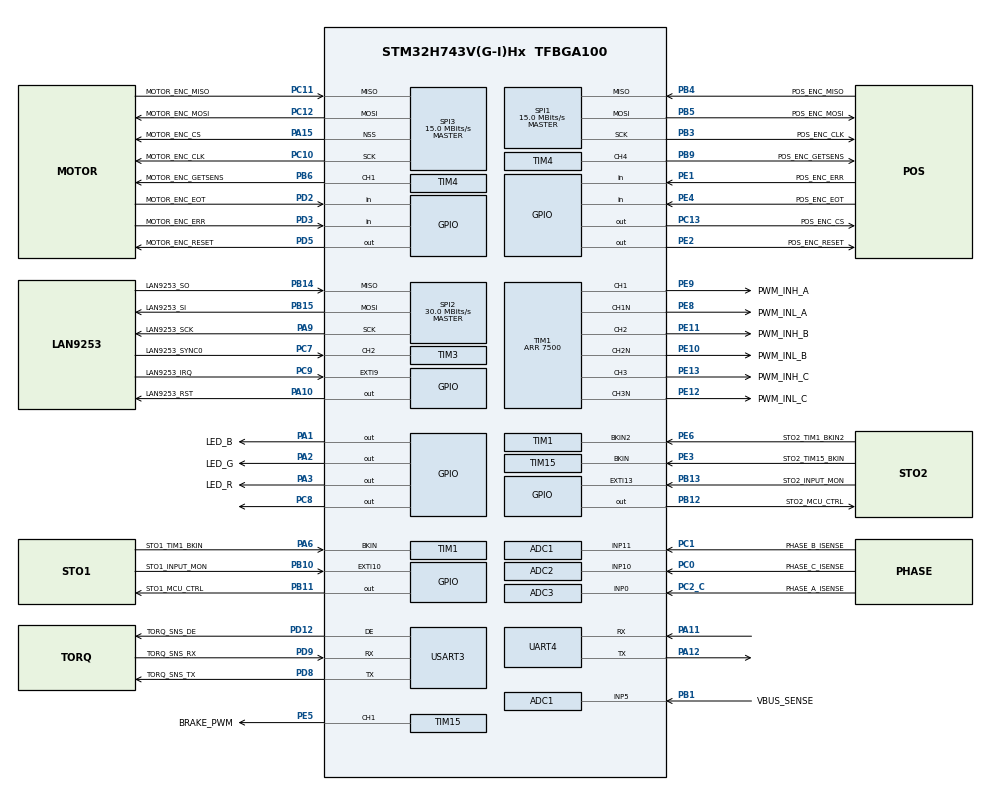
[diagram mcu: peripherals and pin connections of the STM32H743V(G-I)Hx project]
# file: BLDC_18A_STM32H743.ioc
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ADC1.AWD1ITMode=ENABLE
ADC1.Channel-2\#ChannelRegularConversion=ADC_CHANNEL_11
ADC1.ClockPrescaler=ADC_CLOCK_SYNC_PCLK_DIV4
ADC1.ClockPrescalerADC3=ADC_CLOCK_SYNC_PCLK_DIV4
ADC1.EnableAnalogWatchDog1=true
ADC1.EnableInjectedConversion=ENABLE
ADC1.ExternalTrigConv=ADC_EXTERNALTRIG_T2_CC2
ADC1.ExternalTrigConvEdge=ADC_EXTERNALTRIGCONVEDGE_RISINGFALLING
ADC1.ExternalTrigInjecConv=ADC_EXTERNALTRIGINJEC_T1_TRGO2
ADC1.ExternalTrigInjecConvEdge=ADC_EXTERNALTRIGINJECCONV_EDGE_RISING
ADC1.InjNumberOfConversion=2
ADC1.InjectedChannel-3\#ChannelInjectedConversion=ADC_CHANNEL_11
ADC1.InjectedChannel-4\#ChannelInjectedConversion=ADC_CHANNEL_5
ADC1.InjectedOffsetNumber-3\#ChannelInjectedConversion=ADC_OFFSET_NONE
ADC1.InjectedOffsetNumber-4\#ChannelInjectedConversion=ADC_OFFSET_NONE
ADC1.InjectedOffsetSaturation-3\#ChannelInjectedConversion=DISABLE
ADC1.InjectedOffsetSaturation-4\#ChannelInjectedConversion=DISABLE
ADC1.InjectedOffsetSignedSaturation-3\#ChannelInjectedConversion=DISABLE
ADC1.InjectedOffsetSignedSaturation-4\#ChannelInjectedConversion=DISABLE
ADC1.InjectedRank-3\#ChannelInjectedConversion=1
ADC1.InjectedRank-4\#ChannelInjectedConversion=2
ADC1.InjectedSamplingTime-3\#ChannelInjectedConversion=ADC_SAMPLETIME_16CYCLES_5
ADC1.InjectedSamplingTime-4\#ChannelInjectedConversion=ADC_SAMPLETIME_16CYCLES_5
ADC1.Mode=ADC_DUALMODE_INJECSIMULT
ADC1.NbrOfConversionFlag=1
ADC1.OffsetNumber-2\#ChannelRegularConversion=ADC_OFFSET_NONE
ADC1.OffsetSignedSaturation-2\#ChannelRegularConversion=DISABLE
ADC1.Overrun=ADC_OVR_DATA_OVERWRITTEN
ADC1.Rank-2\#ChannelRegularConversion=1
ADC1.SamplingTime-2\#ChannelRegularConversion=ADC_SAMPLETIME_16CYCLES_5
ADC1.WatchdogChannel=ADC_CHANNEL_11
ADC1.master=1
ADC2.AWD1ITMode=ENABLE
ADC2.Channel-3\#ChannelRegularConversion=ADC_CHANNEL_10
ADC2.ClockPrescaler=ADC_CLOCK_SYNC_PCLK_DIV4
ADC2.ClockPrescalerADC3=ADC_CLOCK_SYNC_PCLK_DIV4
ADC2.EnableAnalogWatchDog1=true
ADC2.EnableInjectedConversion=ENABLE
ADC2.EnableRegularConversion=ENABLE
ADC2.InjNumberOfConversion=2
ADC2.InjectedChannel-2\#ChannelInjectedConversion=ADC_CHANNEL_10
ADC2.InjectedChannel-4\#ChannelInjectedConversion=ADC_CHANNEL_10
ADC2.InjectedOffsetNumber-2\#ChannelInjectedConversion=ADC_OFFSET_NONE
ADC2.InjectedOffsetNumber-4\#ChannelInjectedConversion=ADC_OFFSET_NONE
ADC2.InjectedOffsetSaturation-2\#ChannelInjectedConversion=DISABLE
ADC2.InjectedOffsetSaturation-4\#ChannelInjectedConversion=DISABLE
ADC2.InjectedOffsetSignedSaturation-2\#ChannelInjectedConversion=DISABLE
ADC2.InjectedOffsetSignedSaturation-4\#ChannelInjectedConversion=DISABLE
ADC2.InjectedRank-2\#ChannelInjectedConversion=1
ADC2.InjectedRank-4\#ChannelInjectedConversion=2
ADC2.InjectedSamplingTime-2\#ChannelInjectedConversion=ADC_SAMPLETIME_16CYCLES_5
ADC2.InjectedSamplingTime-4\#ChannelInjectedConversion=ADC_SAMPLETIME_16CYCLES_5
ADC2.Mode=ADC_DUALMODE_INJECSIMULT
ADC2.NbrOfConversion=1
ADC2.NbrOfConversionFlag=1
ADC2.OffsetNumber-3\#ChannelRegularConversion=ADC_OFFSET_NONE
ADC2.OffsetSignedSaturation-3\#ChannelRegularConversion=DISABLE
ADC2.Overrun=ADC_OVR_DATA_OVERWRITTEN
ADC2.Rank-3\#ChannelRegularConversion=1
ADC2.SamplingTime-3\#ChannelRegularConversion=ADC_SAMPLETIME_16CYCLES_5
ADC2.WatchdogChannel=ADC_CHANNEL_10
ADC3.AWD1ITMode=ENABLE
ADC3.Channel-3\#ChannelRegularConversion=ADC_CHANNEL_0
ADC3.ClockPrescaler=ADC_CLOCK_SYNC_PCLK_DIV4
ADC3.ClockPrescalerADC3=ADC_CLOCK_SYNC_PCLK_DIV4
ADC3.EnableAnalogWatchDog1=true
ADC3.EnableAnalogWatchDog3=false
ADC3.EnableInjectedConversion=ENABLE
ADC3.EnableRegularConversion=ENABLE
ADC3.ExternalTrigConv=ADC_EXTERNALTRIG_T2_CC2
ADC3.ExternalTrigConvEdge=ADC_EXTERNALTRIGCONVEDGE_RISINGFALLING
ADC3.ExternalTrigInjecConv=ADC_EXTERNALTRIGINJEC_T1_TRGO2
ADC3.ExternalTrigInjecConvEdge=ADC_EXTERNALTRIGINJECCONV_EDGE_RISING
ADC3.InjNumberOfConversion=1
ADC3.InjectedChannel-1\#ChannelInjectedConversion=ADC_CHANNEL_0
ADC3.InjectedOffsetNumber-1\#ChannelInjectedConversion=ADC_OFFSET_NONE
ADC3.InjectedOffsetSaturation-1\#ChannelInjectedConversion=DISABLE
ADC3.InjectedOffsetSignedSaturation-1\#ChannelInjectedConversion=DISABLE
ADC3.InjectedRank-1\#ChannelInjectedConversion=1
ADC3.InjectedSamplingTime-1\#ChannelInjectedConversion=ADC_SAMPLETIME_16CYCLES_5
ADC3.Mode=ADC_DUALMODE_INJECSIMULT
ADC3.MonitoredBy-3\#ChannelRegularConversion=__NULL
ADC3.NbrOfConversionFlag=1
ADC3.OffsetNumber-3\#ChannelRegularConversion=ADC_OFFSET_NONE
ADC3.OffsetSignedSaturation-3\#ChannelRegularConversion=DISABLE
ADC3.Overrun=ADC_OVR_DATA_OVERWRITTEN
ADC3.Rank-3\#ChannelRegularConversion=1
ADC3.SamplingTime-3\#ChannelRegularConversion=ADC_SAMPLETIME_16CYCLES_5
CORTEX_M7.CPU_ICache=Enabled
CORTEX_M7.default_mode_Activation=1
Dma.Request0=SPI3_RX
Dma.Request1=SPI3_TX
Dma.Request2=SPI1_RX
Dma.Request3=SPI1_TX
Dma.Request4=SPI2_RX
Dma.Request5=SPI2_TX
Dma.Request6=USART3_RX
Dma.Request7=USART3_TX
Dma.Request8=TIM4_CH2
Dma.Request9=TIM4_CH3
Dma.SPI1_RX.2.Direction=DMA_PERIPH_TO_MEMORY
Dma.SPI1_RX.2.EventEnable=DISABLE
Dma.SPI1_RX.2.FIFOMode=DMA_FIFOMODE_ENABLE
Dma.SPI1_RX.2.FIFOThreshold=DMA_FIFO_THRESHOLD_HALFFULL
Dma.SPI1_RX.2.Instance=DMA2_Stream0
Dma.SPI1_RX.2.MemBurst=DMA_MBURST_SINGLE
Dma.SPI1_RX.2.MemDataAlignment=DMA_MDATAALIGN_BYTE
Dma.SPI1_RX.2.MemInc=DMA_MINC_ENABLE
Dma.SPI1_RX.2.Mode=DMA_NORMAL
Dma.SPI1_RX.2.PeriphBurst=DMA_PBURST_SINGLE
Dma.SPI1_RX.2.PeriphDataAlignment=DMA_PDATAALIGN_BYTE
Dma.SPI1_RX.2.PeriphInc=DMA_PINC_DISABLE
Dma.SPI1_RX.2.Polarity=HAL_DMAMUX_REQ_GEN_RISING
Dma.SPI1_RX.2.Priority=DMA_PRIORITY_HIGH
Dma.SPI1_RX.2.RequestNumber=1
Dma.SPI1_RX.2.SignalID=NONE
Dma.SPI1_RX.2.SyncEnable=DISABLE
Dma.SPI1_RX.2.SyncPolarity=HAL_DMAMUX_SYNC_NO_EVENT
Dma.SPI1_RX.2.SyncRequestNumber=1
Dma.SPI1_RX.2.SyncSignalID=NONE
Dma.SPI1_TX.3.Direction=DMA_MEMORY_TO_PERIPH
Dma.SPI1_TX.3.EventEnable=DISABLE
Dma.SPI1_TX.3.FIFOMode=DMA_FIFOMODE_ENABLE
Dma.SPI1_TX.3.FIFOThreshold=DMA_FIFO_THRESHOLD_HALFFULL
Dma.SPI1_TX.3.Instance=DMA2_Stream1
Dma.SPI1_TX.3.MemBurst=DMA_MBURST_SINGLE
Dma.SPI1_TX.3.MemDataAlignment=DMA_MDATAALIGN_BYTE
Dma.SPI1_TX.3.MemInc=DMA_MINC_ENABLE
Dma.SPI1_TX.3.Mode=DMA_NORMAL
Dma.SPI1_TX.3.PeriphBurst=DMA_PBURST_SINGLE
Dma.SPI1_TX.3.PeriphDataAlignment=DMA_PDATAALIGN_BYTE
Dma.SPI1_TX.3.PeriphInc=DMA_PINC_DISABLE
Dma.SPI1_TX.3.Polarity=HAL_DMAMUX_REQ_GEN_RISING
Dma.SPI1_TX.3.Priority=DMA_PRIORITY_HIGH
Dma.SPI1_TX.3.RequestNumber=1
Dma.SPI1_TX.3.SignalID=NONE
Dma.SPI1_TX.3.SyncEnable=DISABLE
Dma.SPI1_TX.3.SyncPolarity=HAL_DMAMUX_SYNC_NO_EVENT
Dma.SPI1_TX.3.SyncRequestNumber=1
Dma.SPI1_TX.3.SyncSignalID=NONE
Dma.SPI2_RX.4.Direction=DMA_PERIPH_TO_MEMORY
Dma.SPI2_RX.4.EventEnable=DISABLE
Dma.SPI2_RX.4.FIFOMode=DMA_FIFOMODE_ENABLE
Dma.SPI2_RX.4.FIFOThreshold=DMA_FIFO_THRESHOLD_HALFFULL
Dma.SPI2_RX.4.Instance=DMA2_Stream2
Dma.SPI2_RX.4.MemBurst=DMA_MBURST_SINGLE
Dma.SPI2_RX.4.MemDataAlignment=DMA_MDATAALIGN_BYTE
Dma.SPI2_RX.4.MemInc=DMA_MINC_ENABLE
Dma.SPI2_RX.4.Mode=DMA_NORMAL
Dma.SPI2_RX.4.PeriphBurst=DMA_PBURST_SINGLE
Dma.SPI2_RX.4.PeriphDataAlignment=DMA_PDATAALIGN_BYTE
Dma.SPI2_RX.4.PeriphInc=DMA_PINC_DISABLE
Dma.SPI2_RX.4.Polarity=HAL_DMAMUX_REQ_GEN_RISING
Dma.SPI2_RX.4.Priority=DMA_PRIORITY_MEDIUM
Dma.SPI2_RX.4.RequestNumber=1
Dma.SPI2_RX.4.SignalID=NONE
Dma.SPI2_RX.4.SyncEnable=DISABLE
Dma.SPI2_RX.4.SyncPolarity=HAL_DMAMUX_SYNC_NO_EVENT
Dma.SPI2_RX.4.SyncRequestNumber=1
Dma.SPI2_RX.4.SyncSignalID=NONE
Dma.SPI2_TX.5.Direction=DMA_MEMORY_TO_PERIPH
Dma.SPI2_TX.5.EventEnable=DISABLE
Dma.SPI2_TX.5.FIFOMode=DMA_FIFOMODE_ENABLE
Dma.SPI2_TX.5.FIFOThreshold=DMA_FIFO_THRESHOLD_HALFFULL
Dma.SPI2_TX.5.Instance=DMA2_Stream3
Dma.SPI2_TX.5.MemBurst=DMA_MBURST_SINGLE
Dma.SPI2_TX.5.MemDataAlignment=DMA_MDATAALIGN_BYTE
Dma.SPI2_TX.5.MemInc=DMA_MINC_ENABLE
Dma.SPI2_TX.5.Mode=DMA_NORMAL
Dma.SPI2_TX.5.PeriphBurst=DMA_PBURST_SINGLE
Dma.SPI2_TX.5.PeriphDataAlignment=DMA_PDATAALIGN_BYTE
Dma.SPI2_TX.5.PeriphInc=DMA_PINC_DISABLE
Dma.SPI2_TX.5.Polarity=HAL_DMAMUX_REQ_GEN_RISING
Dma.SPI2_TX.5.Priority=DMA_PRIORITY_MEDIUM
Dma.SPI2_TX.5.RequestNumber=1
Dma.SPI2_TX.5.SignalID=NONE
Dma.SPI2_TX.5.SyncEnable=DISABLE
Dma.SPI2_TX.5.SyncPolarity=HAL_DMAMUX_SYNC_NO_EVENT
Dma.SPI2_TX.5.SyncRequestNumber=1
Dma.SPI2_TX.5.SyncSignalID=NONE
Dma.SPI3_RX.0.Direction=DMA_PERIPH_TO_MEMORY
Dma.SPI3_RX.0.EventEnable=DISABLE
Dma.SPI3_RX.0.FIFOMode=DMA_FIFOMODE_ENABLE
Dma.SPI3_RX.0.FIFOThreshold=DMA_FIFO_THRESHOLD_HALFFULL
Dma.SPI3_RX.0.Instance=DMA1_Stream0
Dma.SPI3_RX.0.MemBurst=DMA_MBURST_SINGLE
Dma.SPI3_RX.0.MemDataAlignment=DMA_MDATAALIGN_BYTE
Dma.SPI3_RX.0.MemInc=DMA_MINC_ENABLE
Dma.SPI3_RX.0.Mode=DMA_NORMAL
Dma.SPI3_RX.0.PeriphBurst=DMA_PBURST_SINGLE
Dma.SPI3_RX.0.PeriphDataAlignment=DMA_PDATAALIGN_BYTE
Dma.SPI3_RX.0.PeriphInc=DMA_PINC_DISABLE
Dma.SPI3_RX.0.Polarity=HAL_DMAMUX_REQ_GEN_RISING
Dma.SPI3_RX.0.Priority=DMA_PRIORITY_HIGH
Dma.SPI3_RX.0.RequestNumber=1
Dma.SPI3_RX.0.SignalID=NONE
Dma.SPI3_RX.0.SyncEnable=DISABLE
Dma.SPI3_RX.0.SyncPolarity=HAL_DMAMUX_SYNC_NO_EVENT
Dma.SPI3_RX.0.SyncRequestNumber=1
Dma.SPI3_RX.0.SyncSignalID=NONE
Dma.SPI3_TX.1.Direction=DMA_MEMORY_TO_PERIPH
Dma.SPI3_TX.1.EventEnable=DISABLE
Dma.SPI3_TX.1.FIFOMode=DMA_FIFOMODE_ENABLE
Dma.SPI3_TX.1.FIFOThreshold=DMA_FIFO_THRESHOLD_HALFFULL
Dma.SPI3_TX.1.Instance=DMA1_Stream1
Dma.SPI3_TX.1.MemBurst=DMA_MBURST_SINGLE
Dma.SPI3_TX.1.MemDataAlignment=DMA_MDATAALIGN_BYTE
Dma.SPI3_TX.1.MemInc=DMA_MINC_ENABLE
Dma.SPI3_TX.1.Mode=DMA_NORMAL
Dma.SPI3_TX.1.PeriphBurst=DMA_PBURST_SINGLE
Dma.SPI3_TX.1.PeriphDataAlignment=DMA_PDATAALIGN_BYTE
Dma.SPI3_TX.1.PeriphInc=DMA_PINC_DISABLE
Dma.SPI3_TX.1.Polarity=HAL_DMAMUX_REQ_GEN_RISING
Dma.SPI3_TX.1.Priority=DMA_PRIORITY_HIGH
Dma.SPI3_TX.1.RequestNumber=1
Dma.SPI3_TX.1.SignalID=NONE
Dma.SPI3_TX.1.SyncEnable=DISABLE
Dma.SPI3_TX.1.SyncPolarity=HAL_DMAMUX_SYNC_NO_EVENT
Dma.SPI3_TX.1.SyncRequestNumber=1
Dma.SPI3_TX.1.SyncSignalID=NONE
Dma.TIM4_CH2.8.Direction=DMA_PERIPH_TO_MEMORY
Dma.TIM4_CH2.8.EventEnable=DISABLE
Dma.TIM4_CH2.8.FIFOMode=DMA_FIFOMODE_DISABLE
Dma.TIM4_CH2.8.Instance=DMA1_Stream2
Dma.TIM4_CH2.8.MemDataAlignment=DMA_MDATAALIGN_WORD
Dma.TIM4_CH2.8.MemInc=DMA_MINC_ENABLE
Dma.TIM4_CH2.8.Mode=DMA_NORMAL
Dma.TIM4_CH2.8.PeriphDataAlignment=DMA_PDATAALIGN_WORD
Dma.TIM4_CH2.8.PeriphInc=DMA_PINC_DISABLE
Dma.TIM4_CH2.8.Polarity=HAL_DMAMUX_REQ_GEN_RISING
Dma.TIM4_CH2.8.Priority=DMA_PRIORITY_VERY_HIGH
Dma.TIM4_CH2.8.RequestNumber=1
Dma.TIM4_CH2.8.SignalID=NONE
Dma.TIM4_CH2.8.SyncEnable=DISABLE
Dma.TIM4_CH2.8.SyncPolarity=HAL_DMAMUX_SYNC_NO_EVENT
Dma.TIM4_CH2.8.SyncRequestNumber=1
Dma.TIM4_CH2.8.SyncSignalID=NONE
Dma.TIM4_CH3.9.Direction=DMA_PERIPH_TO_MEMORY
Dma.TIM4_CH3.9.EventEnable=DISABLE
Dma.TIM4_CH3.9.FIFOMode=DMA_FIFOMODE_DISABLE
Dma.TIM4_CH3.9.Instance=DMA1_Stream3
Dma.TIM4_CH3.9.MemDataAlignment=DMA_MDATAALIGN_WORD
Dma.TIM4_CH3.9.MemInc=DMA_MINC_ENABLE
Dma.TIM4_CH3.9.Mode=DMA_NORMAL
Dma.TIM4_CH3.9.PeriphDataAlignment=DMA_PDATAALIGN_WORD
Dma.TIM4_CH3.9.PeriphInc=DMA_PINC_DISABLE
Dma.TIM4_CH3.9.Polarity=HAL_DMAMUX_REQ_GEN_RISING
Dma.TIM4_CH3.9.Priority=DMA_PRIORITY_VERY_HIGH
Dma.TIM4_CH3.9.RequestNumber=1
Dma.TIM4_CH3.9.SignalID=NONE
Dma.TIM4_CH3.9.SyncEnable=DISABLE
Dma.TIM4_CH3.9.SyncPolarity=HAL_DMAMUX_SYNC_NO_EVENT
Dma.TIM4_CH3.9.SyncRequestNumber=1
Dma.TIM4_CH3.9.SyncSignalID=NONE
Dma.USART3_RX.6.Direction=DMA_PERIPH_TO_MEMORY
Dma.USART3_RX.6.EventEnable=DISABLE
Dma.USART3_RX.6.FIFOMode=DMA_FIFOMODE_DISABLE
Dma.USART3_RX.6.Instance=DMA2_Stream4
Dma.USART3_RX.6.MemDataAlignment=DMA_MDATAALIGN_BYTE
Dma.USART3_RX.6.MemInc=DMA_MINC_ENABLE
Dma.USART3_RX.6.Mode=DMA_NORMAL
Dma.USART3_RX.6.PeriphDataAlignment=DMA_PDATAALIGN_BYTE
Dma.USART3_RX.6.PeriphInc=DMA_PINC_DISABLE
Dma.USART3_RX.6.Polarity=HAL_DMAMUX_REQ_GEN_RISING
Dma.USART3_RX.6.Priority=DMA_PRIORITY_LOW
Dma.USART3_RX.6.RequestNumber=1
Dma.USART3_RX.6.SignalID=NONE
Dma.USART3_RX.6.SyncEnable=DISABLE
Dma.USART3_RX.6.SyncPolarity=HAL_DMAMUX_SYNC_NO_EVENT
Dma.USART3_RX.6.SyncRequestNumber=1
Dma.USART3_RX.6.SyncSignalID=NONE
Dma.USART3_TX.7.Direction=DMA_MEMORY_TO_PERIPH
Dma.USART3_TX.7.EventEnable=DISABLE
Dma.USART3_TX.7.FIFOMode=DMA_FIFOMODE_DISABLE
Dma.USART3_TX.7.Instance=DMA2_Stream5
Dma.USART3_TX.7.MemDataAlignment=DMA_MDATAALIGN_BYTE
Dma.USART3_TX.7.MemInc=DMA_MINC_ENABLE
Dma.USART3_TX.7.Mode=DMA_NORMAL
Dma.USART3_TX.7.PeriphDataAlignment=DMA_PDATAALIGN_BYTE
Dma.USART3_TX.7.PeriphInc=DMA_PINC_DISABLE
Dma.USART3_TX.7.Polarity=HAL_DMAMUX_REQ_GEN_RISING
Dma.USART3_TX.7.Priority=DMA_PRIORITY_LOW
Dma.USART3_TX.7.RequestNumber=1
Dma.USART3_TX.7.SignalID=NONE
Dma.USART3_TX.7.SyncEnable=DISABLE
Dma.USART3_TX.7.SyncPolarity=HAL_DMAMUX_SYNC_NO_EVENT
Dma.USART3_TX.7.SyncRequestNumber=1
Dma.USART3_TX.7.SyncSignalID=NONE
IWDG1.Prescaler=IWDG_PRESCALER_32
IWDG1.Reload=249
IWDG1.Window=4095
Mcu.Family=STM32H7
Mcu.Name=STM32H743V(G-I)Hx
Mcu.Package=TFBGA100
NVIC.ADC3_IRQn=true\:0\:0\:false\:false\:true\:true\:true\:true
NVIC.ADC_IRQn=true\:1\:0\:true\:false\:true\:true\:true\:true
NVIC.DMA1_Stream0_IRQn=true\:10\:0\:true\:false\:true\:false\:true\:true
NVIC.DMA1_Stream1_IRQn=true\:10\:0\:true\:false\:true\:false\:true\:true
NVIC.DMA1_Stream2_IRQn=true\:8\:0\:true\:false\:true\:false\:true\:true
NVIC.DMA1_Stream3_IRQn=true\:8\:0\:true\:false\:true\:false\:true\:true
NVIC.DMA2_Stream0_IRQn=true\:10\:0\:true\:false\:true\:false\:true\:true
NVIC.DMA2_Stream1_IRQn=true\:10\:0\:true\:false\:true\:false\:true\:true
NVIC.DMA2_Stream2_IRQn=true\:5\:0\:true\:false\:true\:false\:true\:true
NVIC.DMA2_Stream3_IRQn=true\:5\:0\:true\:false\:true\:false\:true\:true
NVIC.DMA2_Stream4_IRQn=true\:10\:0\:true\:false\:true\:false\:true\:true
NVIC.DMA2_Stream5_IRQn=true\:10\:0\:true\:false\:true\:false\:true\:true
NVIC.EXTI15_10_IRQn=true\:10\:0\:true\:false\:true\:true\:true\:true
NVIC.EXTI9_5_IRQn=true\:10\:0\:true\:false\:true\:true\:true\:true
NVIC.PriorityGroup=NVIC_PRIORITYGROUP_4
NVIC.SPI1_IRQn=true\:5\:0\:true\:false\:true\:false\:true\:true
NVIC.SPI2_IRQn=true\:8\:0\:true\:false\:true\:false\:true\:true
NVIC.SPI3_IRQn=true\:15\:0\:true\:false\:true\:false\:true\:true
NVIC.TIM1_BRK_IRQn=true\:0\:0\:true\:false\:true\:true\:true\:true
NVIC.TIM3_IRQn=true\:3\:0\:true\:false\:true\:true\:true\:true
NVIC.TIM6_DAC_IRQn=true\:0\:0\:false\:false\:true\:true\:true\:true
NVIC.USART3_IRQn=true\:11\:0\:true\:false\:true\:true\:true\:true
PA1.GPIO_Label=LED_B
PA1.Signal=GPIO_Output
PA10.GPIO_Label=LAN9253_RST
PA10.GPIO_ModeDefaultOutputPP=GPIO_MODE_OUTPUT_OD
PA10.GPIO_PuPd=GPIO_NOPULL
PA10.PinState=GPIO_PIN_SET
PA10.Signal=GPIO_Output
PA11.Mode=Asynchronous
PA11.Signal=UART4_RX
PA12.Mode=Asynchronous
PA12.Signal=UART4_TX
PA13\ (JTMS/SWDIO).Mode=Serial_Wire
PA13\ (JTMS/SWDIO).Signal=DEBUG_JTMS-SWDIO
PA14\ (JTCK/SWCLK).Mode=Serial_Wire
PA14\ (JTCK/SWCLK).Signal=DEBUG_JTCK-SWCLK
PA15\ (JTDI).GPIO_Label=MOTOR_ENC_CS
PA15\ (JTDI).Mode=NSS_Signal_Hard_Output
PA15\ (JTDI).Signal=SPI3_NSS
PA2.GPIO_Label=LED_G
PA2.Signal=GPIO_Output
PA3.GPIO_Label=LED_R
PA3.Signal=GPIO_Output
PA6.GPIO_Label=STO1_TIM1_BKIN
PA6.Mode=Activate-Break-Input
PA6.Signal=TIM1_BKIN
PA9.GPIO_Label=LAN9253_SCK
PA9.GPIO_Speed=GPIO_SPEED_FREQ_HIGH
PA9.Mode=Full_Duplex_Master
PA9.Signal=SPI2_SCK
PB1.GPIO_Label=VBUS_SENSE
PB1.Signal=ADCx_INP5
PB10.GPIO_Label=STO1_INPUT_MON
PB10.GPIO_ModeDefaultEXTI=GPIO_MODE_IT_RISING_FALLING
PB10.Signal=GPXTI10
PB11.GPIO_Label=STO1_MCU_CTRL
PB11.Signal=GPIO_Output
PB12.GPIO_Label=STO2_MCU_CTRL
PB12.Signal=GPIO_Output
PB13.GPIO_Label=STO2_INPUT_MON
PB13.GPIO_ModeDefaultEXTI=GPIO_MODE_IT_RISING_FALLING
PB13.Signal=GPXTI13
PB14.GPIO_Label=LAN9253_SO
PB14.GPIO_Speed=GPIO_SPEED_FREQ_HIGH
PB14.Mode=Full_Duplex_Master
PB14.Signal=SPI2_MISO
PB15.GPIO_Label=LAN9253_SI
PB15.GPIO_Speed=GPIO_SPEED_FREQ_HIGH
PB15.Mode=Full_Duplex_Master
PB15.Signal=SPI2_MOSI
PB3\ (JTDO/TRACESWO).GPIO_Label=POS_ENC_CLK
PB3\ (JTDO/TRACESWO).Mode=Full_Duplex_Master
PB3\ (JTDO/TRACESWO).Signal=SPI1_SCK
PB4\ (NJTRST).GPIO_Label=POS_ENC_MISO
PB4\ (NJTRST).Mode=Full_Duplex_Master
PB4\ (NJTRST).Signal=SPI1_MISO
PB5.GPIO_Label=POS_ENC_MOSI
PB5.Mode=Full_Duplex_Master
PB5.Signal=SPI1_MOSI
PB6.GPIO_Label=MOTOR_ENC_GETSENS
PB6.GPIO_Speed=GPIO_SPEED_FREQ_HIGH
PB6.Signal=S_TIM4_CH1
PB9.GPIO_Label=POS_ENC_GETSENS
PB9.GPIO_Speed=GPIO_SPEED_FREQ_HIGH
PB9.Signal=S_TIM4_CH4
PC0.GPIO_Label=PHASE_C_ISENSE
PC0.Signal=ADCx_INP10
PC1.GPIO_Label=PHASE_B_ISENSE
PC1.Signal=ADCx_INP11
PC10.GPIO_Label=MOTOR_ENC_CLK
PC10.GPIO_Speed=GPIO_SPEED_FREQ_HIGH
PC10.Mode=Full_Duplex_Master
PC10.Signal=SPI3_SCK
PC11.GPIO_Label=MOTOR_ENC_MISO
PC11.GPIO_Speed=GPIO_SPEED_FREQ_HIGH
PC11.Mode=Full_Duplex_Master
PC11.Signal=SPI3_MISO
PC12.GPIO_Label=MOTOR_ENC_MOSI
PC12.GPIO_Speed=GPIO_SPEED_FREQ_HIGH
PC12.Mode=Full_Duplex_Master
PC12.Signal=SPI3_MOSI
PC13.GPIO_Label=POS_ENC_CS
PC13.PinState=GPIO_PIN_SET
PC13.Signal=GPIO_Output
PC2_C.GPIO_Label=PHASE_A_ISENSE
PC2_C.Mode=IN0-Single-Ended
PC2_C.Signal=ADC3_INP0
PC7.GPIO_Label=LAN9253_SYNC0
PC7.Signal=S_TIM3_CH2
PC8.Signal=GPIO_Output
PC9.GPIO_Label=LAN9253_IRQ
PC9.GPIO_ModeDefaultEXTI=GPIO_MODE_IT_FALLING
PC9.Signal=GPXTI9
PD12.GPIO_Label=TORQ_SNS_DE
PD12.GPIO_Speed=GPIO_SPEED_FREQ_HIGH
PD12.Mode=Hardware Flow Control (RS485)
PD12.Signal=USART3_DE
PD2.GPIO_Label=MOTOR_ENC_EOT
PD2.Signal=GPIO_Input
PD3.GPIO_Label=MOTOR_ENC_ERR
PD3.Signal=GPIO_Input
PD5.GPIO_Label=MOTOR_ENC_RESET
PD5.PinState=GPIO_PIN_SET
PD5.Signal=GPIO_Output
PD8.GPIO_Label=TORQ_SNS_TX
PD8.GPIO_Speed=GPIO_SPEED_FREQ_HIGH
PD8.Mode=Asynchronous
PD8.Signal=USART3_TX
PD9.GPIO_Label=TORQ_SNS_RX
PD9.GPIO_Speed=GPIO_SPEED_FREQ_HIGH
PD9.Mode=Asynchronous
PD9.Signal=USART3_RX
PE1.GPIO_Label=POS_ENC_ERR
PE1.Signal=GPIO_Input
PE10.GPIO_Label=PWM_INL_B
PE10.GPIO_Speed=GPIO_SPEED_FREQ_HIGH
PE10.Mode=PWM Generation2 CH2 CH2N
PE10.Signal=TIM1_CH2N
PE11.GPIO_Label=PWM_INH_B
PE11.GPIO_Speed=GPIO_SPEED_FREQ_HIGH
PE11.Signal=S_TIM1_CH2
PE12.GPIO_Label=PWM_INL_C
PE12.GPIO_Speed=GPIO_SPEED_FREQ_HIGH
PE12.Mode=PWM Generation3 CH3 CH3N
PE12.Signal=TIM1_CH3N
PE13.GPIO_Label=PWM_INH_C
PE13.GPIO_Speed=GPIO_SPEED_FREQ_HIGH
PE13.Signal=S_TIM1_CH3
PE2.GPIO_Label=POS_ENC_RESET
PE2.PinState=GPIO_PIN_SET
PE2.Signal=GPIO_Output
PE3.GPIO_Label=STO2_TIM15_BKIN
PE3.Mode=Activate-Break-Input
PE3.Signal=TIM15_BKIN
PE4.GPIO_Label=POS_ENC_EOT
PE4.Signal=GPIO_Input
PE5.GPIO_Label=BRAKE_PWM
PE5.Signal=S_TIM15_CH1
PE6.GPIO_Label=STO2_TIM1_BKIN2
PE6.Mode=Activate-Break-Input-2
PE6.Signal=TIM1_BKIN2
PE8.GPIO_Label=PWM_INL_A
PE8.GPIO_Speed=GPIO_SPEED_FREQ_HIGH
PE8.Mode=PWM Generation1 CH1 CH1N
PE8.Signal=TIM1_CH1N
PE9.GPIO_Label=PWM_INH_A
PE9.GPIO_Speed=GPIO_SPEED_FREQ_HIGH
PE9.Signal=S_TIM1_CH1
PH0-OSC_IN\ (PH0).Mode=HSE-External-Oscillator
PH0-OSC_IN\ (PH0).Signal=RCC_OSC_IN
PH1-OSC_OUT\ (PH1).Mode=HSE-External-Oscillator
PH1-OSC_OUT\ (PH1).Signal=RCC_OSC_OUT
ProjectManager.HeapSize=0x200
ProjectManager.StackSize=0x400
ProjectManager.TargetToolchain=CMake
RCC.ADCFreq_Value=76125000
RCC.APB1Freq_Value=120000000
RCC.APB2Freq_Value=120000000
RCC.APB3Freq_Value=120000000
RCC.APB4Freq_Value=120000000
RCC.CortexFreq_Value=480000000
RCC.D1PPRE=RCC_APB3_DIV2
RCC.D2PPRE1=RCC_APB1_DIV2
RCC.D2PPRE2=RCC_APB2_DIV2
RCC.D3PPRE=RCC_APB4_DIV2
RCC.DIVM1=4
RCC.DIVM2=4
RCC.DIVN1=160
RCC.DIVN2=25
RCC.DIVQ1=8
RCC.HCLKFreq_Value=240000000
RCC.HPRE=RCC_HCLK_DIV2
RCC.HSE_VALUE=24000000
RCC.PLL2FRACN=3072
RCC.PLLFRACN=0
RCC.PLLSourceVirtual=RCC_PLLSOURCE_HSE
RCC.SYSCLKFreq_VALUE=480000000
RCC.SYSCLKSource=RCC_SYSCLKSOURCE_PLLCLK
RCC.USBFreq_Value=120000000
SH.ADCx_INP10.0=ADC2_INP10,IN10-Single-Ended
SH.ADCx_INP11.0=ADC1_INP11,IN11-Single-Ended
SH.ADCx_INP5.0=ADC1_INP5,IN5-Single-Ended
SH.S_TIM15_CH1.0=TIM15_CH1,PWM Generation1 CH1
SH.S_TIM1_CH1.0=TIM1_CH1,PWM Generation1 CH1 CH1N
SH.S_TIM1_CH2.0=TIM1_CH2,PWM Generation2 CH2 CH2N
SH.S_TIM1_CH3.0=TIM1_CH3,PWM Generation3 CH3 CH3N
SH.S_TIM3_CH2.0=TIM3_CH2,Input_Capture2_from_TI2
SH.S_TIM4_CH1.0=TIM4_CH1,PWM Generation1 CH1
SH.S_TIM4_CH4.0=TIM4_CH4,PWM Generation4 CH4
SPI1.BaudRatePrescaler=SPI_BAUDRATEPRESCALER_8
SPI1.CalculateBaudRate=15.0 MBits/s
SPI1.DataSize=SPI_DATASIZE_8BIT
SPI1.Direction=SPI_DIRECTION_2LINES
SPI1.MasterKeepIOState=SPI_MASTER_KEEP_IO_STATE_ENABLE
SPI1.MasterSSIdleness=SPI_MASTER_SS_IDLENESS_01CYCLE
SPI1.Mode=SPI_MODE_MASTER
SPI1.VirtualType=VM_MASTER
SPI2.BaudRatePrescaler=SPI_BAUDRATEPRESCALER_4
SPI2.CalculateBaudRate=30.0 MBits/s
SPI2.DataSize=SPI_DATASIZE_8BIT
SPI2.Direction=SPI_DIRECTION_2LINES
SPI2.Mode=SPI_MODE_MASTER
SPI2.VirtualType=VM_MASTER
SPI3.BaudRatePrescaler=SPI_BAUDRATEPRESCALER_8
SPI3.CalculateBaudRate=15.0 MBits/s
SPI3.DataSize=SPI_DATASIZE_8BIT
SPI3.Direction=SPI_DIRECTION_2LINES
SPI3.MasterKeepIOState=SPI_MASTER_KEEP_IO_STATE_ENABLE
SPI3.MasterSSIdleness=SPI_MASTER_SS_IDLENESS_01CYCLE
SPI3.Mode=SPI_MODE_MASTER
SPI3.VirtualNSS=VM_NSSHARD
SPI3.VirtualType=VM_MASTER
TIM1.AutoReloadPreload=TIM_AUTORELOAD_PRELOAD_ENABLE
TIM1.Break2Polarity=TIM_BREAK2POLARITY_LOW
TIM1.BreakPolarity=TIM_BREAKPOLARITY_LOW
TIM1.Channel-PWM\ Generation1\ CH1\ CH1N=TIM_CHANNEL_1
TIM1.Channel-PWM\ Generation2\ CH2\ CH2N=TIM_CHANNEL_2
TIM1.Channel-PWM\ Generation3\ CH3\ CH3N=TIM_CHANNEL_3
TIM1.Channel-PWM\ Generation4\ No\ Output=TIM_CHANNEL_4
TIM1.Channel-PWM\ Generation5\ No\ Output=TIM_CHANNEL_5
TIM1.CounterMode=TIM_COUNTERMODE_CENTERALIGNED1
TIM1.DeadTime=60
TIM1.OCMode_PWM-PWM\ Generation4\ No\ Output=TIM_OCMODE_PWM2
TIM1.OCMode_PWM-PWM\ Generation5\ No\ Output=TIM_OCMODE_PWM2
TIM1.Period=7500
TIM1.Pulse-PWM\ Generation4\ No\ Output=2625
TIM1.Pulse-PWM\ Generation5\ No\ Output=7480
TIM1.RepetitionCounter=1
TIM1.SourceBRK2DigInputPolarity=TIM_BREAKINPUTSOURCE_POLARITY_LOW
TIM1.SourceBRKDigInputPolarity=TIM_BREAKINPUTSOURCE_POLARITY_LOW
TIM1.TIM_MasterOutputTrigger=TIM_TRGO_OC4REF
TIM1.TIM_MasterOutputTrigger2=TIM_TRGO2_OC5REF
TIM15.Channel-PWM\ Generation1\ CH1=TIM_CHANNEL_1
TIM15.OffStateIDLEMode=TIM_OSSI_ENABLE
TIM15.OffStateRunMode=TIM_OSSR_ENABLE
TIM15.Period=14999
TIM2.Channel-Output\ Compare2\ No\ Output=TIM_CHANNEL_2
TIM2.OCMode_2=TIM_OCMODE_TOGGLE
TIM2.Period=749
TIM2.TIM_MasterOutputTrigger=TIM_TRGO_UPDATE
TIM3.Channel-Input_Capture2_from_TI2=TIM_CHANNEL_2
TIM3.ICFilter_CH2=2
TIM3.Prescaler=0
TIM4.Channel-Output\ Compare2\ No\ Output=TIM_CHANNEL_2
TIM4.Channel-Output\ Compare3\ No\ Output=TIM_CHANNEL_3
TIM4.Channel-PWM\ Generation1\ CH1=TIM_CHANNEL_1
TIM4.Channel-PWM\ Generation4\ CH4=TIM_CHANNEL_4
TIM4.Period=65535
TIM4.Prescaler=0
TIM4.Pulse-Output\ Compare2\ No\ Output=1440
TIM4.Pulse-Output\ Compare3\ No\ Output=1440
TIM4.Pulse-PWM\ Generation1\ CH1=240
TIM4.Pulse-PWM\ Generation4\ CH4=240
TIM6.Period=99
TIM6.Prescaler=239
USART3.UART_DEAssertionTime=2
USART3.UART_DEDeassertionTime=1
USART3.VirtualMode-Asynchronous=VM_ASYNC
USART3.VirtualMode-Hardware\ Flow\ Control\ (RS485)=VM_ASYNC
VP_IWDG1_VS_IWDG.Mode=IWDG_Activate
VP_MEMORYMAP_VS_MEMORYMAP.Mode=CurAppReg
VP_TIM15_VS_ClockSourceINT.Mode=Internal
VP_TIM1_VS_ClockSourceINT.Mode=Internal
VP_TIM1_VS_no_output4.Mode=PWM Generation4 No Output
VP_TIM1_VS_no_output5.Mode=PWM Generation5 No Output
VP_TIM2_VS_ClockSourceITR.Mode=TriggerSource_ITR0
VP_TIM2_VS_ControllerModeReset.Mode=Reset Mode
VP_TIM2_VS_no_output2.Mode=Output Compare2 No Output
VP_TIM3_VS_ClockSourceINT.Mode=Internal
VP_TIM3_VS_ClockSourceITR.Mode=TriggerSource_ITR0
VP_TIM3_VS_ControllerModeReset.Mode=Reset Mode
VP_TIM4_VS_ClockSourceINT.Mode=Internal
VP_TIM4_VS_ClockSourceITR.Mode=TriggerSource_ITR0
VP_TIM4_VS_ControllerModeReset.Mode=Reset Mode
VP_TIM4_VS_no_output2.Mode=Output Compare2 No Output
VP_TIM4_VS_no_output3.Mode=Output Compare3 No Output
VP_TIM5_VS_ClockSourceINT.Mode=Internal
VP_TIM6_VS_ClockSourceINT.Mode=Enable_Timer
VP_TIM6_VS_OPM.Mode=OPM_bit
board=custom

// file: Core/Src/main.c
/* USER CODE BEGIN Header */
/**
  ******************************************************************************
  * @file           : main.c
  * @brief          : Main program body
  ******************************************************************************
  * @attention
  *
  * Copyright (c) 2026 STMicroelectronics.
  * All rights reserved.
  *
  * This software is licensed under terms that can be found in the LICENSE file
  * in the root directory of this software component.
  * If no LICENSE file comes with this software, it is provided AS-IS.
  *
  ******************************************************************************
  */
/* USER CODE END Header */
#include "main.h"
#include "adc.h"
#include "dma.h"
#include "iwdg.h"
#include "spi.h"
#include "tim.h"
#include "usart.h"
#include "gpio.h"

/* USER CODE BEGIN Includes */
#include "servo_main.h"
/* USER CODE END Includes */

void SystemClock_Config(void);
static void MPU_Config(void);

int main(void)
{

  /* MPU Configuration--------------------------------------------------------*/
  MPU_Config();

  /* Enable the CPU Cache */

  /* Enable I-Cache---------------------------------------------------------*/
  SCB_EnableICache();

  /* MCU Configuration--------------------------------------------------------*/

  /* Reset of all peripherals, Initializes the Flash interface and the Systick. */
  HAL_Init();

  /* Configure the system clock */
  SystemClock_Config();

  /* Initialize all configured peripherals */
  MX_GPIO_Init();
  MX_DMA_Init();
  MX_ADC1_Init();
  MX_ADC2_Init();
  MX_ADC3_Init();
  MX_SPI1_Init();
  MX_SPI2_Init();
  MX_SPI3_Init();
  MX_TIM1_Init();
  MX_TIM15_Init();
  MX_UART4_Init();
  MX_USART3_UART_Init();
  MX_TIM3_Init();
  MX_TIM4_Init();
  MX_IWDG1_Init();
  MX_TIM2_Init();
  MX_TIM5_Init();
  MX_TIM6_Init();
  /* USER CODE BEGIN 2 */
   servo_main();
  /* USER CODE END 2 */

  /* Infinite loop */
  while (1)
  {

  }
}

void SystemClock_Config(void)
{
  RCC_OscInitTypeDef RCC_OscInitStruct = {0};
  RCC_ClkInitTypeDef RCC_ClkInitStruct = {0};

  /** Supply configuration update enable
  */
  HAL_PWREx_ConfigSupply(PWR_LDO_SUPPLY);

  /** Configure the main internal regulator output voltage
  */
  __HAL_PWR_VOLTAGESCALING_CONFIG(PWR_REGULATOR_VOLTAGE_SCALE0);

  while(!__HAL_PWR_GET_FLAG(PWR_FLAG_VOSRDY)) {}

  /** Initializes the RCC Oscillators according to the specified parameters
  * in the RCC_OscInitTypeDef structure.
  */
  RCC_OscInitStruct.OscillatorType = RCC_OSCILLATORTYPE_LSI|RCC_OSCILLATORTYPE_HSE;
  RCC_OscInitStruct.HSEState = RCC_HSE_ON;
  RCC_OscInitStruct.LSIState = RCC_LSI_ON;
  RCC_OscInitStruct.PLL.PLLState = RCC_PLL_ON;
  RCC_OscInitStruct.PLL.PLLSource = RCC_PLLSOURCE_HSE;
  RCC_OscInitStruct.PLL.PLLM = 4;
  RCC_OscInitStruct.PLL.PLLN = 160;
  RCC_OscInitStruct.PLL.PLLP = 2;
  RCC_OscInitStruct.PLL.PLLQ = 8;
  RCC_OscInitStruct.PLL.PLLR = 2;
  RCC_OscInitStruct.PLL.PLLRGE = RCC_PLL1VCIRANGE_2;
  RCC_OscInitStruct.PLL.PLLVCOSEL = RCC_PLL1VCOWIDE;
  RCC_OscInitStruct.PLL.PLLFRACN = 0;
  if (HAL_RCC_OscConfig(&RCC_OscInitStruct) != HAL_OK)
  {
    Error_Handler();
  }

  /** Initializes the CPU, AHB and APB buses clocks
  */
  RCC_ClkInitStruct.ClockType = RCC_CLOCKTYPE_HCLK|RCC_CLOCKTYPE_SYSCLK
                              |RCC_CLOCKTYPE_PCLK1|RCC_CLOCKTYPE_PCLK2
                              |RCC_CLOCKTYPE_D3PCLK1|RCC_CLOCKTYPE_D1PCLK1;
  RCC_ClkInitStruct.SYSCLKSource = RCC_SYSCLKSOURCE_PLLCLK;
  RCC_ClkInitStruct.SYSCLKDivider = RCC_SYSCLK_DIV1;
  RCC_ClkInitStruct.AHBCLKDivider = RCC_HCLK_DIV2;
  RCC_ClkInitStruct.APB3CLKDivider = RCC_APB3_DIV2;
  RCC_ClkInitStruct.APB1CLKDivider = RCC_APB1_DIV2;
  RCC_ClkInitStruct.APB2CLKDivider = RCC_APB2_DIV2;
  RCC_ClkInitStruct.APB4CLKDivider = RCC_APB4_DIV2;

  if (HAL_RCC_ClockConfig(&RCC_ClkInitStruct, FLASH_LATENCY_4) != HAL_OK)
  {
    Error_Handler();
  }
}

 /* MPU Configuration */

void MPU_Config(void)
{
  MPU_Region_InitTypeDef MPU_InitStruct = {0};

  /* Disables the MPU */
  HAL_MPU_Disable();

  /** Initializes and configures the Region and the memory to be protected
  */
  MPU_InitStruct.Enable = MPU_REGION_ENABLE;
  MPU_InitStruct.Number = MPU_REGION_NUMBER0;
  MPU_InitStruct.BaseAddress = 0x0;
  MPU_InitStruct.Size = MPU_REGION_SIZE_4GB;
  MPU_InitStruct.SubRegionDisable = 0x87;
  MPU_InitStruct.TypeExtField = MPU_TEX_LEVEL0;
  MPU_InitStruct.AccessPermission = MPU_REGION_NO_ACCESS;
  MPU_InitStruct.DisableExec = MPU_INSTRUCTION_ACCESS_DISABLE;
  MPU_InitStruct.IsShareable = MPU_ACCESS_SHAREABLE;
  MPU_InitStruct.IsCacheable = MPU_ACCESS_NOT_CACHEABLE;
  MPU_InitStruct.IsBufferable = MPU_ACCESS_NOT_BUFFERABLE;

  HAL_MPU_ConfigRegion(&MPU_InitStruct);
  /* Enables the MPU */
  HAL_MPU_Enable(MPU_PRIVILEGED_DEFAULT);

}

void Error_Handler(void)
{
  __disable_irq();
  while (1)
  {
  }
}
